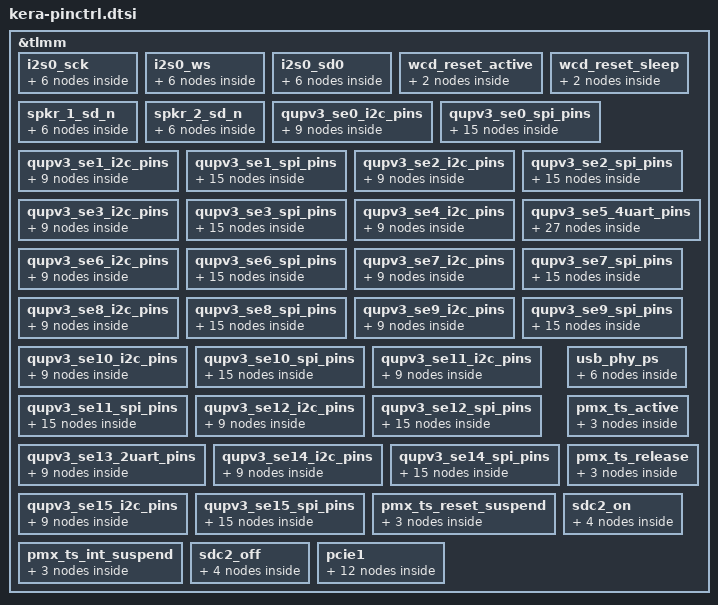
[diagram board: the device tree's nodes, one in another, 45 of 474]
// SPDX-License-Identifier: BSD-3-Clause
/*
 * Copyright (c) 2024 Qualcomm Innovation Center, Inc. All rights reserved.
 */

&tlmm {
	i2s0_sck {
		i2s0_sck_sleep: i2s0_sck_sleep {
			mux {
				pins = "gpio60";
				function = "gpio";
			};

			config {
				pins = "gpio60";
				drive-strength = <2>;   /* 2 mA */
				bias-pull-down;         /* PULL DOWN */
				input-enable;
			};
		};

		i2s0_sck_active: i2s0_sck_active {
			mux {
				pins = "gpio60";
				function = "i2s0_sck";
			};

			config {
				pins = "gpio60";
				drive-strength = <8>;   /* 8 mA */
				bias-disable;           /* NO PULL */
				output-high;
			};
		};
	};

	i2s0_ws {
		i2s0_ws_sleep: i2s0_ws_sleep {
			mux {
				pins = "gpio61";
				function = "gpio";
			};

			config {
				pins = "gpio61";
				drive-strength = <2>;   /* 2 mA */
				bias-pull-down;         /* PULL DOWN */
				input-enable;
			};
		};

		i2s0_ws_active: i2s0_ws_active {
			mux {
				pins = "gpio61";
				function = "i2s0_ws";
			};

			config {
				pins = "gpio61";
				drive-strength = <8>;   /* 8 mA */
				bias-disable;           /* NO PULL */
				output-high;
			};
		};
	};

	i2s0_sd0 {
		i2s0_sd0_sleep: i2s0_sd0_sleep {
			mux {
				pins = "gpio64";
				function = "gpio";
			};

			config {
				pins = "gpio64";
				drive-strength = <2>;   /* 2 mA */
				bias-pull-down;         /* PULL DOWN */
				input-enable;
			};
		};

		i2s0_sd0_active: i2s0_sd0_active {
			mux {
				pins = "gpio64";
				function = "i2s0_data0";
			};

			config {
				pins = "gpio64";
				drive-strength = <8>;   /* 8 mA */
				bias-disable;           /* NO PULL */
				output-high;
			};
		};
	};

	/* WCD reset pin */
	wcd_reset_active: wcd_reset_active {
		mux {
			pins = "gpio150";
			function = "gpio";
		};

		config {
			pins = "gpio150";
			drive-strength = <16>;
			output-high;
		};
	};

	wcd_reset_sleep: wcd_reset_sleep {
		mux {
			pins = "gpio150";
			function = "gpio";
		};

		config {
			pins = "gpio150";
			drive-strength = <16>;
			bias-disable;
			output-low;
		};
	};

/* WSA speaker reset pins  North Pins*/
	spkr_1_sd_n {
		spkr_1_sd_n_sleep: spkr_1_sd_n_sleep {
			mux {
				pins = "gpio59";
				function = "gpio";
			};

			config {
				pins = "gpio59";
				drive-strength = <2>;   /* 2 mA */
				bias-pull-down;
				input-enable;
			};
		};

		spkr_1_sd_n_active: spkr_1_sd_n_active {
			mux {
				pins = "gpio59";
				function = "gpio";
			};

			config {
				pins = "gpio59";
				drive-strength = <16>;   /* 16 mA */
				bias-disable;
				output-high;
			};
		};
	};

/* WSA speaker reset pins  south Pins*/
	spkr_2_sd_n {
		spkr_2_sd_n_sleep: spkr_2_sd_n_sleep {
			mux {
				pins = "gpio69";
				function = "gpio";
			};

			config {
				pins = "gpio69";
				drive-strength = <2>;   /* 2 mA */
				bias-pull-down;
				input-enable;
			};
		};

		spkr_2_sd_n_active: spkr_2_sd_n_active {
			mux {
				pins = "gpio69";
				function = "gpio";
			};

			config {
				pins = "gpio69";
				drive-strength = <16>;   /* 16 mA */
				bias-disable;
				output-high;
			};
		};
	};

	qupv3_se0_i2c_pins: qupv3_se0_i2c_pins {
		qupv3_se0_i2c_sda_active: qupv3_se0_i2c_sda_active {
			mux {
				pins = "gpio28";
				function = "qup1_se0_l0";
			};

			config {
				pins = "gpio28";
				drive-strength = <2>;
				bias-pull-up;
				qcom,i2c_pull;
			};
		};

		qupv3_se0_i2c_scl_active: qupv3_se0_i2c_scl_active {
			mux {
				pins = "gpio29";
				function = "qup1_se0_l1";
			};

			config {
				pins = "gpio29";
				drive-strength = <2>;
				bias-pull-up;
				qcom,i2c_pull;
			};
		};

		qupv3_se0_i2c_sleep: qupv3_se0_i2c_sleep {
			mux {
				pins = "gpio28", "gpio29";
				function = "gpio";
			};

			config {
				pins = "gpio28", "gpio29";
				drive-strength = <2>;
			};
		};
	};

	qupv3_se0_spi_pins: qupv3_se0_spi_pins {
		qupv3_se0_spi_miso_active: qupv3_se0_spi_miso_active {
			mux {
				pins = "gpio28";
				function = "qup1_se0_l0";
			};

			config {
				pins = "gpio28";
				drive-strength = <6>;
				bias-disable;
			};
		};

		qupv3_se0_spi_mosi_active: qupv3_se0_spi_mosi_active {
			mux {
				pins = "gpio29";
				function = "qup1_se0_l1";
			};

			config {
				pins = "gpio29";
				drive-strength = <6>;
				bias-disable;
			};
		};

		qupv3_se0_spi_clk_active: qupv3_se0_spi_clk_active {
			mux {
				pins = "gpio30";
				function = "qup1_se0_l2";
			};

			config {
				pins = "gpio30";
				drive-strength = <6>;
				bias-disable;
			};
		};

		qupv3_se0_spi_cs_active: qupv3_se0_spi_cs_active {
			mux {
				pins = "gpio31";
				function = "qup1_se0_l3";
			};

			config {
				pins = "gpio31";
				drive-strength = <6>;
				bias-disable;
			};
		};

		qupv3_se0_spi_sleep: qupv3_se0_spi_sleep {
			mux {
				pins = "gpio28", "gpio29",
					"gpio30", "gpio31";
				function = "gpio";
			};

			config {
				pins = "gpio28", "gpio29",
					"gpio30", "gpio31";
				drive-strength = <2>;
				bias-disable;
			};
		};
	};

	qupv3_se1_i2c_pins: qupv3_se1_i2c_pins {
		qupv3_se1_i2c_sda_active: qupv3_se1_i2c_sda_active {
			mux {
				pins = "gpio32";
				function = "qup1_se1_l0";
			};

			config {
				pins = "gpio32";
				drive-strength = <2>;
				bias-pull-up;
				qcom,i2c_pull;
			};
		};

		qupv3_se1_i2c_scl_active: qupv3_se1_i2c_scl_active {
			mux {
				pins = "gpio33";
				function = "qup1_se1_l1";
			};

			config {
				pins = "gpio33";
				drive-strength = <2>;
				bias-pull-up;
				qcom,i2c_pull;
			};
		};

		qupv3_se1_i2c_sleep: qupv3_se1_i2c_sleep {
			mux {
				pins = "gpio32", "gpio33";
				function = "gpio";
			};

			config {
				pins = "gpio32", "gpio33";
				drive-strength = <2>;
			};
		};
	};

	qupv3_se1_spi_pins: qupv3_se1_spi_pins {
		qupv3_se1_spi_miso_active: qupv3_se1_spi_miso_active {
			mux {
				pins = "gpio32";
				function = "qup1_se1_l0";
			};

			config {
				pins = "gpio32";
				drive-strength = <6>;
				bias-disable;
			};
		};

		qupv3_se1_spi_mosi_active: qupv3_se1_spi_mosi_active {
			mux {
				pins = "gpio33";
				function = "qup1_se1_l1";
			};

			config {
				pins = "gpio33";
				drive-strength = <6>;
				bias-disable;
			};
		};

		qupv3_se1_spi_clk_active: qupv3_se1_spi_clk_active {
			mux {
				pins = "gpio34";
				function = "qup1_se1_l2";
			};

			config {
				pins = "gpio34";
				drive-strength = <6>;
				bias-disable;
			};
		};

		qupv3_se1_spi_cs_active: qupv3_se1_spi_cs_active {
			mux {
				pins = "gpio35";
				function = "qup1_se1_l3";
			};

			config {
				pins = "gpio35";
				drive-strength = <6>;
				bias-disable;
			};
		};

		qupv3_se1_spi_sleep: qupv3_se1_spi_sleep {
			mux {
				pins = "gpio32", "gpio33",
					"gpio34", "gpio35";
				function = "gpio";
			};

			config {
				pins = "gpio32", "gpio33",
					"gpio34", "gpio35";
				drive-strength = <2>;
				bias-disable;
			};
		};
	};

	qupv3_se2_i2c_pins: qupv3_se2_i2c_pins {
		qupv3_se2_i2c_sda_active: qupv3_se2_i2c_sda_active {
			mux {
				pins = "gpio52";
				function = "qup1_se2_l0";
			};

			config {
				pins = "gpio52";
				drive-strength = <2>;
				bias-pull-up;
				qcom,i2c_pull;
			};
		};

		qupv3_se2_i2c_scl_active: qupv3_se2_i2c_scl_active {
			mux {
				pins = "gpio53";
				function = "qup1_se2_l1";
			};

			config {
				pins = "gpio53";
				drive-strength = <2>;
				bias-pull-up;
				qcom,i2c_pull;
			};
		};

		qupv3_se2_i2c_sleep: qupv3_se2_i2c_sleep {
			mux {
				pins = "gpio52", "gpio53";
				function = "gpio";
			};

			config {
				pins = "gpio52", "gpio53";
				drive-strength = <2>;
			};
		};
	};

	qupv3_se2_spi_pins: qupv3_se2_spi_pins {
		qupv3_se2_spi_miso_active: qupv3_se2_spi_miso_active {
			mux {
				pins = "gpio52";
				function = "qup1_se2_l0";
			};

			config {
				pins = "gpio52";
				drive-strength = <6>;
				bias-disable;
			};
		};

		qupv3_se2_spi_mosi_active: qupv3_se2_spi_mosi_active {
			mux {
				pins = "gpio53";
				function = "qup1_se2_l1";
			};

			config {
				pins = "gpio53";
				drive-strength = <6>;
				bias-disable;
			};
		};

		qupv3_se2_spi_clk_active: qupv3_se2_spi_clk_active {
			mux {
				pins = "gpio54";
				function = "qup1_se2_l2_mira";
			};

			config {
				pins = "gpio54";
				drive-strength = <6>;
				bias-disable;
			};
		};

		qupv3_se2_spi_cs_active: qupv3_se2_spi_cs_active {
			mux {
				pins = "gpio55";
				function = "qup1_se2_l3_mira";
			};

			config {
				pins = "gpio55";
				drive-strength = <6>;
				bias-disable;
			};
		};

		qupv3_se2_spi_sleep: qupv3_se2_spi_sleep {
			mux {
				pins = "gpio52", "gpio53",
					"gpio54", "gpio55";
				function = "gpio";
			};

			config {
				pins = "gpio52", "gpio53",
					"gpio54", "gpio55";
				drive-strength = <2>;
				bias-disable;
			};
		};
	};

	qupv3_se3_i2c_pins: qupv3_se3_i2c_pins {
		qupv3_se3_i2c_sda_active: qupv3_se3_i2c_sda_active {
			mux {
				pins = "gpio44";
				function = "qup1_se3_l0";
			};

			config {
				pins = "gpio44";
				drive-strength = <2>;
				bias-pull-up;
				qcom,i2c_pull;
			};
		};

		qupv3_se3_i2c_scl_active: qupv3_se3_i2c_scl_active {
			mux {
				pins = "gpio45";
				function = "qup1_se3_l1";
			};

			config {
				pins = "gpio45";
				drive-strength = <2>;
				bias-pull-up;
				qcom,i2c_pull;
			};
		};

		qupv3_se3_i2c_sleep: qupv3_se3_i2c_sleep {
			mux {
				pins = "gpio44", "gpio45";
				function = "gpio";
			};

			config {
				pins = "gpio44", "gpio45";
				drive-strength = <2>;
			};
		};
	};

	qupv3_se3_spi_pins: qupv3_se3_spi_pins {
		qupv3_se3_spi_miso_active: qupv3_se3_spi_miso_active {
			mux {
				pins = "gpio44";
				function = "qup1_se3_l0";
			};

			config {
				pins = "gpio44";
				drive-strength = <6>;
				bias-disable;
			};
		};

		qupv3_se3_spi_mosi_active: qupv3_se3_spi_mosi_active {
			mux {
				pins = "gpio45";
				function = "qup1_se3_l1";
			};

			config {
				pins = "gpio45";
				drive-strength = <6>;
				bias-disable;
			};
		};

		qupv3_se3_spi_clk_active: qupv3_se3_spi_clk_active {
			mux {
				pins = "gpio46";
				function = "qup1_se3_l2";
			};

			config {
				pins = "gpio46";
				drive-strength = <6>;
				bias-disable;
			};
		};

		qupv3_se3_spi_cs_active: qupv3_se3_spi_cs_active {
			mux {
				pins = "gpio47";
				function = "qup1_se3_l3";
			};

			config {
				pins = "gpio47";
				drive-strength = <6>;
				bias-disable;
			};
		};

		qupv3_se3_spi_sleep: qupv3_se3_spi_sleep {
			mux {
				pins = "gpio44", "gpio45",
					"gpio46", "gpio47";
				function = "gpio";
			};

			config {
				pins = "gpio44", "gpio45",
					"gpio46", "gpio47";
				drive-strength = <2>;
				bias-disable;
			};
		};
	};

	qupv3_se4_i2c_pins: qupv3_se4_i2c_pins {
		qupv3_se4_i2c_sda_active: qupv3_se4_i2c_sda_active {
			mux {
				pins = "gpio36";
				function = "qup1_se4_l0";
			};

			config {
				pins = "gpio36";
				drive-strength = <2>;
				bias-pull-up;
				qcom,i2c_pull;
			};
		};

		qupv3_se4_i2c_scl_active: qupv3_se4_i2c_scl_active {
			mux {
				pins = "gpio37";
				function = "qup1_se4_l1";
			};

			config {
				pins = "gpio37";
				drive-strength = <2>;
				bias-pull-up;
				qcom,i2c_pull;
			};
		};

		qupv3_se4_i2c_sleep: qupv3_se4_i2c_sleep {
			mux {
				pins = "gpio36", "gpio37";
				function = "gpio";
			};

			config {
				pins = "gpio36", "gpio37";
				drive-strength = <2>;
			};
		};
	};

	qupv3_se5_4uart_pins: qupv3_se5_4uart_pins {
		qupv3_se5_default_cts: qupv3_se5_default_cts {
			mux {
				pins = "gpio132";
				function = "gpio";
			};

			config {
				pins = "gpio132";
				drive-strength = <2>;
				bias-disable;
			};
		};

		qupv3_se5_default_rts: qupv3_se5_default_rts {
			mux {
				pins = "gpio133";
				function = "gpio";
			};

			config {
				pins = "gpio133";
				drive-strength = <2>;
				bias-pull-down;
			};
		};

		qupv3_se5_default_tx: qupv3_se5_default_tx {
			mux {
				pins = "gpio134";
				function = "gpio";
			};

			config {
				pins = "gpio134";
				drive-strength = <2>;
				bias-pull-up;
			};
		};

		qupv3_se5_default_rx: qupv3_se5_default_rx {
			mux {
				pins = "gpio135";
				function = "gpio";
			};

			config {
				pins = "gpio135";
				drive-strength = <2>;
				bias-pull-down;
			};
		};

		qupv3_se5_cts: qupv3_se5_cts {
			mux {
				pins = "gpio132";
				function = "qup1_se5_l0";
			};

			config {
				pins = "gpio132";
				drive-strength = <2>;
				bias-disable;
			};
		};

		qupv3_se5_rts: qupv3_se5_rts {
			mux {
				pins = "gpio133";
				function = "qup1_se5_l1";
			};

			config {
				pins = "gpio133";
				drive-strength = <2>;
				bias-pull-down;
			};
		};

		qupv3_se5_tx: qupv3_se5_tx {
			mux {
				pins = "gpio134";
				function = "qup1_se5_l2";
			};

			config {
				pins = "gpio134";
				drive-strength = <2>;
				bias-pull-up;
			};
		};

		qupv3_se5_rx_active: qupv3_se5_rx_active {
			mux {
				pins = "gpio135";
				function = "qup1_se5_l3";
			};

			config {
				pins = "gpio135";
				drive-strength = <2>;
				bias-disable;
			};
		};

		/* RX to be in gpio mode for sleep config */
		qupv3_se5_rx_wake: qupv3_se5_rx_wake {
			mux {
				pins = "gpio135";
				function = "gpio";
			};

			config {
				pins = "gpio135";
				drive-strength = <2>;
				bias-disable;
			};
		};
	};

	qupv3_se6_i2c_pins: qupv3_se6_i2c_pins {
		qupv3_se6_i2c_sda_active: qupv3_se6_i2c_sda_active {
			mux {
				pins = "gpio40";
				function = "qup1_se6_l0";
			};

			config {
				pins = "gpio40";
				drive-strength = <2>;
				bias-pull-up;
				qcom,i2c_pull;
			};
		};

		qupv3_se6_i2c_scl_active: qupv3_se6_i2c_scl_active {
			mux {
				pins = "gpio54";
				function = "qup1_se6_l1_mirb";
			};

			config {
				pins = "gpio54";
				drive-strength = <2>;
				bias-pull-up;
				qcom,i2c_pull;
			};
		};

		qupv3_se6_i2c_sleep: qupv3_se6_i2c_sleep {
			mux {
				pins = "gpio40", "gpio54";
				function = "gpio";
			};

			config {
				pins = "gpio40", "gpio54";
				drive-strength = <2>;
			};
		};
	};

	qupv3_se6_spi_pins: qupv3_se6_spi_pins {
		qupv3_se6_spi_miso_active: qupv3_se6_spi_miso_active {
			mux {
				pins = "gpio40";
				function = "qup1_se6_l0";
			};

			config {
				pins = "gpio40";
				drive-strength = <6>;
				bias-disable;
			};
		};

		qupv3_se6_spi_mosi_active: qupv3_se6_spi_mosi_active {
			mux {
				pins = "gpio54";
				function = "qup1_se6_l1_mirb";
			};

			config {
				pins = "gpio54";
				drive-strength = <6>;
				bias-disable;
			};
		};

		qupv3_se6_spi_clk_active: qupv3_se6_spi_clk_active {
			mux {
				pins = "gpio42";
				function = "qup1_se6_l2";
			};

			config {
				pins = "gpio42";
				drive-strength = <6>;
				bias-disable;
			};
		};

		qupv3_se6_spi_cs_active: qupv3_se6_spi_cs_active {
			mux {
				pins = "gpio55";
				function = "qup1_se6_l3_mirb";
			};

			config {
				pins = "gpio55";
				drive-strength = <6>;
				bias-disable;
			};
		};

		qupv3_se6_spi_sleep: qupv3_se6_spi_sleep {
			mux {
				pins = "gpio40", "gpio54",
					"gpio42", "gpio55";
				function = "gpio";
			};

			config {
				pins = "gpio40", "gpio54",
					"gpio42", "gpio55";
				drive-strength = <2>;
				bias-disable;
			};
		};
	};

	qupv3_se7_i2c_pins: qupv3_se7_i2c_pins {
		qupv3_se7_i2c_sda_active: qupv3_se7_i2c_sda_active {
			mux {
				pins = "gpio81";
				function = "qup1_se7_l0_mira";
			};

			config {
				pins = "gpio81";
				drive-strength = <2>;
				bias-pull-up;
				qcom,i2c_pull;
			};
		};

		qupv3_se7_i2c_scl_active: qupv3_se7_i2c_scl_active {
			mux {
				pins = "gpio80";
				function = "qup1_se7_l1_mira";
			};

			config {
				pins = "gpio80";
				drive-strength = <2>;
				bias-pull-up;
				qcom,i2c_pull;
			};
		};

		qupv3_se7_i2c_sleep: qupv3_se7_i2c_sleep {
			mux {
				pins = "gpio81", "gpio80";
				function = "gpio";
			};

			config {
				pins = "gpio81", "gpio80";
				drive-strength = <2>;
			};
		};
	};

	qupv3_se7_spi_pins: qupv3_se7_spi_pins {
		qupv3_se7_spi_miso_active: qupv3_se7_spi_miso_active {
			mux {
				pins = "gpio81";
				function = "qup1_se7_l0_mira";
			};

			config {
				pins = "gpio81";
				drive-strength = <6>;
				bias-disable;
			};
		};

		qupv3_se7_spi_mosi_active: qupv3_se7_spi_mosi_active {
			mux {
				pins = "gpio80";
				function = "qup1_se7_l1_mira";
			};

			config {
				pins = "gpio80";
				drive-strength = <6>;
				bias-disable;
			};
		};

		qupv3_se7_spi_clk_active: qupv3_se7_spi_clk_active {
			mux {
				pins = "gpio114";
				function = "qup1_se7_l2";
			};

			config {
				pins = "gpio114";
				drive-strength = <6>;
				bias-disable;
			};
		};

		qupv3_se7_spi_cs_active: qupv3_se7_spi_cs_active {
			mux {
				pins = "gpio78";
				function = "qup1_se7_l3";
			};

			config {
				pins = "gpio78";
				drive-strength = <6>;
				bias-disable;
			};
		};

		qupv3_se7_spi_sleep: qupv3_se7_spi_sleep {
			mux {
				pins = "gpio81", "gpio80",
					"gpio114", "gpio78";
				function = "gpio";
			};

			config {
				pins = "gpio81", "gpio80",
					"gpio114", "gpio78";
				drive-strength = <2>;
				bias-disable;
			};
		};
	};

	qupv3_se8_i2c_pins: qupv3_se8_i2c_pins {
		qupv3_se8_i2c_sda_active: qupv3_se8_i2c_sda_active {
			mux {
				pins = "gpio0";
				function = "qup2_se0_l0";
			};

			config {
				pins = "gpio0";
				drive-strength = <2>;
				bias-pull-up;
				qcom,i2c_pull;
			};
		};

		qupv3_se8_i2c_scl_active: qupv3_se8_i2c_scl_active {
			mux {
				pins = "gpio1";
				function = "qup2_se0_l1";
			};

			config {
				pins = "gpio1";
				drive-strength = <2>;
				bias-pull-up;
				qcom,i2c_pull;
			};
		};

		qupv3_se8_i2c_sleep: qupv3_se8_i2c_sleep {
			mux {
				pins = "gpio0", "gpio1";
				function = "gpio";
			};

			config {
				pins = "gpio0", "gpio1";
				drive-strength = <2>;
			};
		};
	};

	qupv3_se8_spi_pins: qupv3_se8_spi_pins {
		qupv3_se8_spi_miso_active: qupv3_se8_spi_miso_active {
			mux {
				pins = "gpio0";
				function = "qup2_se0_l0";
			};

			config {
				pins = "gpio0";
				drive-strength = <6>;
				bias-disable;
			};
		};

		qupv3_se8_spi_mosi_active: qupv3_se8_spi_mosi_active {
			mux {
				pins = "gpio1";
				function = "qup2_se0_l1";
			};

			config {
				pins = "gpio1";
				drive-strength = <6>;
				bias-disable;
			};
		};

		qupv3_se8_spi_clk_active: qupv3_se8_spi_clk_active {
			mux {
				pins = "gpio2";
				function = "qup2_se0_l2";
			};

			config {
				pins = "gpio2";
				drive-strength = <6>;
				bias-disable;
			};
		};

		qupv3_se8_spi_cs_active: qupv3_se8_spi_cs_active {
			mux {
				pins = "gpio3";
				function = "qup2_se0_l3";
			};

			config {
				pins = "gpio3";
				drive-strength = <6>;
				bias-disable;
			};
		};

		qupv3_se8_spi_sleep: qupv3_se8_spi_sleep {
			mux {
				pins = "gpio0", "gpio1",
					"gpio2", "gpio3";
				function = "gpio";
			};

			config {
				pins = "gpio0", "gpio1",
					"gpio2", "gpio3";
				drive-strength = <2>;
				bias-disable;
			};
		};
	};

	qupv3_se9_i2c_pins: qupv3_se9_i2c_pins {
		qupv3_se9_i2c_sda_active: qupv3_se9_i2c_sda_active {
			mux {
				pins = "gpio4";
				function = "qup2_se1_l0";
			};

			config {
				pins = "gpio4";
				drive-strength = <2>;
				bias-pull-up;
				qcom,i2c_pull;
			};
		};

		qupv3_se9_i2c_scl_active: qupv3_se9_i2c_scl_active {
			mux {
				pins = "gpio5";
				function = "qup2_se1_l1";
			};

			config {
				pins = "gpio5";
				drive-strength = <2>;
				bias-pull-up;
				qcom,i2c_pull;
			};
		};

		qupv3_se9_i2c_sleep: qupv3_se9_i2c_sleep {
			mux {
				pins = "gpio4", "gpio5";
				function = "gpio";
			};

			config {
				pins = "gpio4", "gpio5";
				drive-strength = <2>;
			};
		};
	};

	qupv3_se9_spi_pins: qupv3_se9_spi_pins {
		qupv3_se9_spi_miso_active: qupv3_se9_spi_miso_active {
			mux {
				pins = "gpio4";
				function = "qup2_se1_l0";
			};

			config {
				pins = "gpio4";
				drive-strength = <6>;
				bias-disable;
			};
		};

		qupv3_se9_spi_mosi_active: qupv3_se9_spi_mosi_active {
			mux {
				pins = "gpio5";
				function = "qup2_se1_l1";
			};

			config {
				pins = "gpio5";
				drive-strength = <6>;
				bias-disable;
			};
		};

		qupv3_se9_spi_clk_active: qupv3_se9_spi_clk_active {
			mux {
				pins = "gpio6";
				function = "qup2_se1_l2";
			};

			config {
				pins = "gpio6";
				drive-strength = <6>;
				bias-disable;
			};
		};

		qupv3_se9_spi_cs_active: qupv3_se9_spi_cs_active {
			mux {
				pins = "gpio7";
				function = "qup2_se1_l3";
			};

			config {
				pins = "gpio7";
				drive-strength = <6>;
				bias-disable;
			};
		};

		qupv3_se9_spi_sleep: qupv3_se9_spi_sleep {
			mux {
				pins = "gpio4", "gpio5",
					"gpio6", "gpio7";
				function = "gpio";
			};

			config {
				pins = "gpio4", "gpio5",
					"gpio6", "gpio7";
				drive-strength = <2>;
				bias-disable;
			};
		};
	};

	qupv3_se10_i2c_pins: qupv3_se10_i2c_pins {
		qupv3_se10_i2c_sda_active: qupv3_se10_i2c_sda_active {
			mux {
				pins = "gpio8";
				function = "qup2_se2_l0";
			};

			config {
				pins = "gpio8";
				drive-strength = <2>;
				bias-pull-up;
				qcom,i2c_pull;
			};
		};

		qupv3_se10_i2c_scl_active: qupv3_se10_i2c_scl_active {
			mux {
				pins = "gpio9";
				function = "qup2_se2_l1";
			};

			config {
				pins = "gpio9";
				drive-strength = <2>;
				bias-pull-up;
				qcom,i2c_pull;
			};
		};

		qupv3_se10_i2c_sleep: qupv3_se10_i2c_sleep {
			mux {
				pins = "gpio8", "gpio9";
				function = "gpio";
			};

			config {
				pins = "gpio8", "gpio9";
				drive-strength = <2>;
			};
		};
	};

	qupv3_se10_spi_pins: qupv3_se10_spi_pins {
		qupv3_se10_spi_miso_active: qupv3_se10_spi_miso_active {
			mux {
				pins = "gpio8";
				function = "qup2_se2_l0";
			};

			config {
				pins = "gpio8";
				drive-strength = <6>;
				bias-disable;
			};
		};

		qupv3_se10_spi_mosi_active: qupv3_se10_spi_mosi_active {
			mux {
				pins = "gpio9";
				function = "qup2_se2_l1";
			};

			config {
				pins = "gpio9";
				drive-strength = <6>;
				bias-disable;
			};
		};

		qupv3_se10_spi_clk_active: qupv3_se10_spi_clk_active {
			mux {
				pins = "gpio10";
				function = "qup2_se2_l2";
			};

			config {
				pins = "gpio10";
				drive-strength = <6>;
				bias-disable;
			};
		};

		qupv3_se10_spi_cs_active: qupv3_se10_spi_cs_active {
			mux {
				pins = "gpio11";
				function = "qup2_se2_l3";
			};

			config {
				pins = "gpio11";
				drive-strength = <6>;
				bias-disable;
			};
		};

		qupv3_se10_spi_sleep: qupv3_se10_spi_sleep {
			mux {
				pins = "gpio8", "gpio9",
					"gpio10", "gpio11";
				function = "gpio";
			};

			config {
				pins = "gpio8", "gpio9",
					"gpio10", "gpio11";
				drive-strength = <2>;
				bias-disable;
			};
		};
	};

	qupv3_se11_i2c_pins: qupv3_se11_i2c_pins {
		qupv3_se11_i2c_sda_active: qupv3_se11_i2c_sda_active {
			mux {
				pins = "gpio79";
				function = "qup2_se3_l0_mira";
			};

			config {
				pins = "gpio79";
				drive-strength = <2>;
				bias-pull-up;
				qcom,i2c_pull;
			};
		};

		qupv3_se11_i2c_scl_active: qupv3_se11_i2c_scl_active {
			mux {
				pins = "gpio97";
				function = "qup2_se3_l1_mira";
			};

			config {
				pins = "gpio97";
				drive-strength = <2>;
				bias-pull-up;
				qcom,i2c_pull;
			};
		};

		qupv3_se11_i2c_sleep: qupv3_se11_i2c_sleep {
			mux {
				pins = "gpio79", "gpio97";
				function = "gpio";
			};

			config {
				pins = "gpio79", "gpio97";
				drive-strength = <2>;
			};
		};
	};

	qupv3_se11_spi_pins: qupv3_se11_spi_pins {
		qupv3_se11_spi_miso_active: qupv3_se11_spi_miso_active {
			mux {
				pins = "gpio79";
				function = "qup2_se3_l0_mira";
			};

			config {
				pins = "gpio79";
				drive-strength = <6>;
				bias-disable;
			};
		};

		qupv3_se11_spi_mosi_active: qupv3_se11_spi_mosi_active {
			mux {
				pins = "gpio97";
				function = "qup2_se3_l1_mira";
			};

			config {
				pins = "gpio97";
				drive-strength = <6>;
				bias-disable;
			};
		};

		qupv3_se11_spi_clk_active: qupv3_se11_spi_clk_active {
			mux {
				pins = "gpio100";
				function = "qup2_se3_l2";
			};

			config {
				pins = "gpio100";
				drive-strength = <6>;
				bias-disable;
			};
		};

		qupv3_se11_spi_cs_active: qupv3_se11_spi_cs_active {
			mux {
				pins = "gpio116";
				function = "qup2_se3_l3";
			};

			config {
				pins = "gpio116";
				drive-strength = <6>;
				bias-disable;
			};
		};

		qupv3_se11_spi_sleep: qupv3_se11_spi_sleep {
			mux {
				pins = "gpio79", "gpio97",
					"gpio100", "gpio116";
				function = "gpio";
			};

			config {
				pins = "gpio79", "gpio97",
					"gpio100", "gpio116";
				drive-strength = <2>;
				bias-disable;
			};
		};
	};

	qupv3_se12_i2c_pins: qupv3_se12_i2c_pins {
		qupv3_se12_i2c_sda_active: qupv3_se12_i2c_sda_active {
			mux {
				pins = "gpio12";
				function = "qup2_se4_l0";
			};

			config {
				pins = "gpio12";
				drive-strength = <2>;
				bias-pull-up;
				qcom,i2c_pull;
			};
		};

		qupv3_se12_i2c_scl_active: qupv3_se12_i2c_scl_active {
			mux {
				pins = "gpio13";
				function = "qup2_se4_l1";
			};

			config {
				pins = "gpio13";
				drive-strength = <2>;
				bias-pull-up;
				qcom,i2c_pull;
			};
		};

		qupv3_se12_i2c_sleep: qupv3_se12_i2c_sleep {
			mux {
				pins = "gpio12", "gpio13";
				function = "gpio";
			};

			config {
				pins = "gpio12", "gpio13";
				drive-strength = <2>;
			};
		};
	};

	qupv3_se12_spi_pins: qupv3_se12_spi_pins {
		qupv3_se12_spi_miso_active: qupv3_se12_spi_miso_active {
			mux {
				pins = "gpio12";
				function = "qup2_se4_l0";
			};

			config {
				pins = "gpio12";
				drive-strength = <6>;
				bias-disable;
			};
		};

		qupv3_se12_spi_mosi_active: qupv3_se12_spi_mosi_active {
			mux {
				pins = "gpio13";
				function = "qup2_se4_l1";
			};

			config {
				pins = "gpio13";
				drive-strength = <6>;
				bias-disable;
			};
		};

		qupv3_se12_spi_clk_active: qupv3_se12_spi_clk_active {
			mux {
				pins = "gpio26";
				function = "qup2_se4_l2";
			};

			config {
				pins = "gpio26";
				drive-strength = <6>;
				bias-disable;
			};
		};

		qupv3_se12_spi_cs_active: qupv3_se12_spi_cs_active {
			mux {
				pins = "gpio27";
				function = "qup2_se4_l3";
			};

			config {
				pins = "gpio27";
				drive-strength = <6>;
				bias-disable;
			};
		};

		qupv3_se12_spi_sleep: qupv3_se12_spi_sleep {
			mux {
				pins = "gpio12", "gpio13",
					"gpio26", "gpio27";
				function = "gpio";
			};

			config {
				pins = "gpio12", "gpio13",
					"gpio26", "gpio27";
				drive-strength = <2>;
				bias-disable;
			};
		};
	};

	qupv3_se13_2uart_pins: qupv3_se13_2uart_pins {
		qupv3_se13_2uart_tx_active: qupv3_se13_2uart_tx_active {
			mux {
				pins = "gpio18";
				function = "qup2_se5_l2";
			};

			config {
				pins = "gpio18";
				drive-strength = <2>;
				bias-disable;
			};
		};

		qupv3_se13_2uart_rx_active: qupv3_se13_2uart_rx_active {
			mux {
				pins = "gpio19";
				function = "qup2_se5_l3";
			};

			config {
				pins = "gpio19";
				drive-strength = <2>;
				bias-disable;
			};
		};

		qupv3_se13_2uart_sleep: qupv3_se13_2uart_sleep {
			mux {
				pins = "gpio18", "gpio19";
				function = "gpio";
			};

			config {
				pins = "gpio18", "gpio19";
				drive-strength = <2>;
				bias-pull-down;
			};
		};
	};

	qupv3_se14_i2c_pins: qupv3_se14_i2c_pins {
		qupv3_se14_i2c_sda_active: qupv3_se14_i2c_sda_active {
			mux {
				pins = "gpio20";
				function = "qup2_se6_l0";
			};

			config {
				pins = "gpio20";
				drive-strength = <2>;
				bias-pull-up;
				qcom,i2c_pull;
			};
		};

		qupv3_se14_i2c_scl_active: qupv3_se14_i2c_scl_active {
			mux {
				pins = "gpio21";
				function = "qup2_se6_l1";
			};

			config {
				pins = "gpio21";
				drive-strength = <2>;
				bias-pull-up;
				qcom,i2c_pull;
			};
		};

		qupv3_se14_i2c_sleep: qupv3_se14_i2c_sleep {
			mux {
				pins = "gpio20", "gpio21";
				function = "gpio";
			};

			config {
				pins = "gpio20", "gpio21";
				drive-strength = <2>;
			};
		};
	};

	qupv3_se14_spi_pins: qupv3_se14_spi_pins {
		qupv3_se14_spi_miso_active: qupv3_se14_spi_miso_active {
			mux {
				pins = "gpio20";
				function = "qup2_se6_l0";
			};

			config {
				pins = "gpio20";
				drive-strength = <6>;
				bias-disable;
			};
		};

		qupv3_se14_spi_mosi_active: qupv3_se14_spi_mosi_active {
			mux {
				pins = "gpio21";
				function = "qup2_se6_l1";
			};

			config {
				pins = "gpio21";
				drive-strength = <6>;
				bias-disable;
			};
		};

		qupv3_se14_spi_clk_active: qupv3_se14_spi_clk_active {
			mux {
				pins = "gpio22";
				function = "qup2_se6_l2";
			};

			config {
				pins = "gpio22";
				drive-strength = <6>;
				bias-disable;
			};
		};

		qupv3_se14_spi_cs_active: qupv3_se14_spi_cs_active {
			mux {
				pins = "gpio23";
				function = "qup2_se6_l3";
			};

			config {
				pins = "gpio23";
				drive-strength = <6>;
				bias-disable;
			};
		};

		qupv3_se14_spi_sleep: qupv3_se14_spi_sleep {
			mux {
				pins = "gpio20", "gpio21",
					"gpio22", "gpio23";
				function = "gpio";
			};

			config {
				pins = "gpio20", "gpio21",
					"gpio22", "gpio23";
				drive-strength = <2>;
				bias-disable;
			};
		};
	};

	qupv3_se15_i2c_pins: qupv3_se15_i2c_pins {
		qupv3_se15_i2c_sda_active: qupv3_se15_i2c_sda_active {
			mux {
				pins = "gpio27";
				function = "qup2_se7_l0";
			};

			config {
				pins = "gpio27";
				drive-strength = <2>;
				bias-pull-up;
				qcom,i2c_pull;
			};
		};

		qupv3_se15_i2c_scl_active: qupv3_se15_i2c_scl_active {
			mux {
				pins = "gpio26";
				function = "qup2_se7_l1";
			};

			config {
				pins = "gpio26";
				drive-strength = <2>;
				bias-pull-up;
				qcom,i2c_pull;
			};
		};

		qupv3_se15_i2c_sleep: qupv3_se15_i2c_sleep {
			mux {
				pins = "gpio27", "gpio26";
				function = "gpio";
			};

			config {
				pins = "gpio27", "gpio26";
				drive-strength = <2>;
			};
		};
	};

	qupv3_se15_spi_pins: qupv3_se15_spi_pins {
		qupv3_se15_spi_miso_active: qupv3_se15_spi_miso_active {
			mux {
				pins = "gpio27";
				function = "qup2_se7_l0";
			};

			config {
				pins = "gpio27";
				drive-strength = <6>;
				bias-disable;
			};
		};

		qupv3_se15_spi_mosi_active: qupv3_se15_spi_mosi_active {
			mux {
				pins = "gpio26";
				function = "qup2_se7_l1";
			};

			config {
				pins = "gpio26";
				drive-strength = <6>;
				bias-disable;
			};
		};

		qupv3_se15_spi_clk_active: qupv3_se15_spi_clk_active {
			mux {
				pins = "gpio13";
				function = "qup2_se7_l2";
			};

			config {
				pins = "gpio13";
				drive-strength = <6>;
				bias-disable;
			};
		};

		qupv3_se15_spi_cs_active: qupv3_se15_spi_cs_active {
			mux {
				pins = "gpio12";
				function = "qup2_se7_l3";
			};

			config {
				pins = "gpio12";
				drive-strength = <6>;
				bias-disable;
			};
		};

		qupv3_se15_spi_sleep: qupv3_se15_spi_sleep {
			mux {
				pins = "gpio27", "gpio26",
					"gpio13", "gpio12";
				function = "gpio";
			};

			config {
				pins = "gpio27", "gpio26",
					"gpio13", "gpio12";
				drive-strength = <2>;
				bias-disable;
			};
		};
	};

	usb_phy_ps: usb_phy_ps {
		usb3phy_portselect_default: usb3phy_portselect_default {
			mux {
				pins = "gpio122";
				function = "usb0_phy_ps";
			};

			config {
				pins = "gpio122";
				bias-pull-down;
				drive-strength = <2>;
			};
		};

		usb3phy_portselect_gpio: usb3phy_portselect_gpio {
			mux {
				pins = "gpio122";
				function = "gpio";
			};

			config {
				pins = "gpio122";
				drive-strength = <2>;
				bias-pull-down;
				input-enable;
			};
		};
	};

	/* touchscreen pins */
	pmx_ts_active {
		ts_active: ts_active {
			mux {
				pins = "gpio16", "gpio13";
				function = "gpio";
			};

			config {
				pins = "gpio16", "gpio13";
				drive-strength = <8>;
				bias-pull-up;
			};
		};
	};

	pmx_ts_reset_suspend {
		ts_reset_suspend: ts_reset_suspend {
			mux {
				pins = "gpio16";
				function = "gpio";
			};

			config {
				pins = "gpio16";
				drive-strength = <2>;
				bias-pull-down;
			};
		};
	};

	pmx_ts_int_suspend {
		ts_int_suspend: ts_int_suspend {
			mux {
				pins = "gpio13";
				function = "gpio";
			};

			config {
				pins = "gpio13";
				drive-strength = <2>;
				bias-pull-down;
			};
		};
	};

	pmx_ts_release {
		ts_release: ts_release {
			mux {
				pins = "gpio16", "gpio13";
				function = "gpio";
			};

			config {
				pins = "gpio16", "gpio13";
				drive-strength = <2>;
				bias-disable;
			};
		};
	};

	/* sdcc2 pins */
	sdc2_on: sdc2_on {
		clk {
			pins = "gpio62";
			function = "SDC2_CLK";
			bias-disable;
			drive-strength = <16>;
		};

		cmd {
			pins = "gpio51";
			function = "SDC2_CMD";
			bias-pull-up;
			drive-strength = <10>;
		};

		data {
			pins = "gpio38", "gpio39", "gpio48", "gpio49";
			function = "SDC2_DATA";
			bias-pull-up;
			drive-strength = <10>;
		};

		sd-cd {
			pins = "gpio58";
			bias-pull-up;
			drive-strength = <2>;
		};
	};

	sdc2_off: sdc2_off {
		clk {
			pins = "gpio62";
			function = "gpio";
			bias-disable;
			drive-strength = <2>;
		};

		cmd {
			pins = "gpio51";
			function = "gpio";
			bias-pull-up;
			drive-strength = <2>;
		};

		data {
			pins = "gpio38", "gpio39", "gpio48", "gpio49";
			function = "gpio";
			bias-pull-up;
			drive-strength = <2>;
		};

		sd-cd {
			pins = "gpio58";
			bias-pull-up;
			drive-strength = <2>;
		};
	};

	pcie1 {
		pcie1_perst_default: pcie1_perst_default {
			mux {
				pins = "gpio54";
				function = "gpio";
			};

			config {
				pins = "gpio54";
				drive-strength = <2>;
				bias-pull-down;
			};
		};

		pcie1_clkreq_default: pcie1_clkreq_default {
			mux {
				pins = "gpio52";
				function = "pcie1_clk_req_n";
			};

			config {
				pins = "gpio52";
				drive-strength = <2>;
				bias-pull-up;
			};
		};

		pcie1_wake_default: pcie1_wake_default {
			mux {
				pins = "gpio53";
				function = "gpio";
			};

			config {
				pins = "gpio53";
				drive-strength = <2>;
				bias-pull-up;
			};
		};

		pcie1_clkreq_sleep: pcie1_clkreq_sleep {
			mux {
				pins = "gpio52";
				function = "gpio";
			};

			config {
				pins = "gpio52";
				drive-strength = <2>;
				bias-pull-up;
				input-enable;
			};
		};
	};
};
